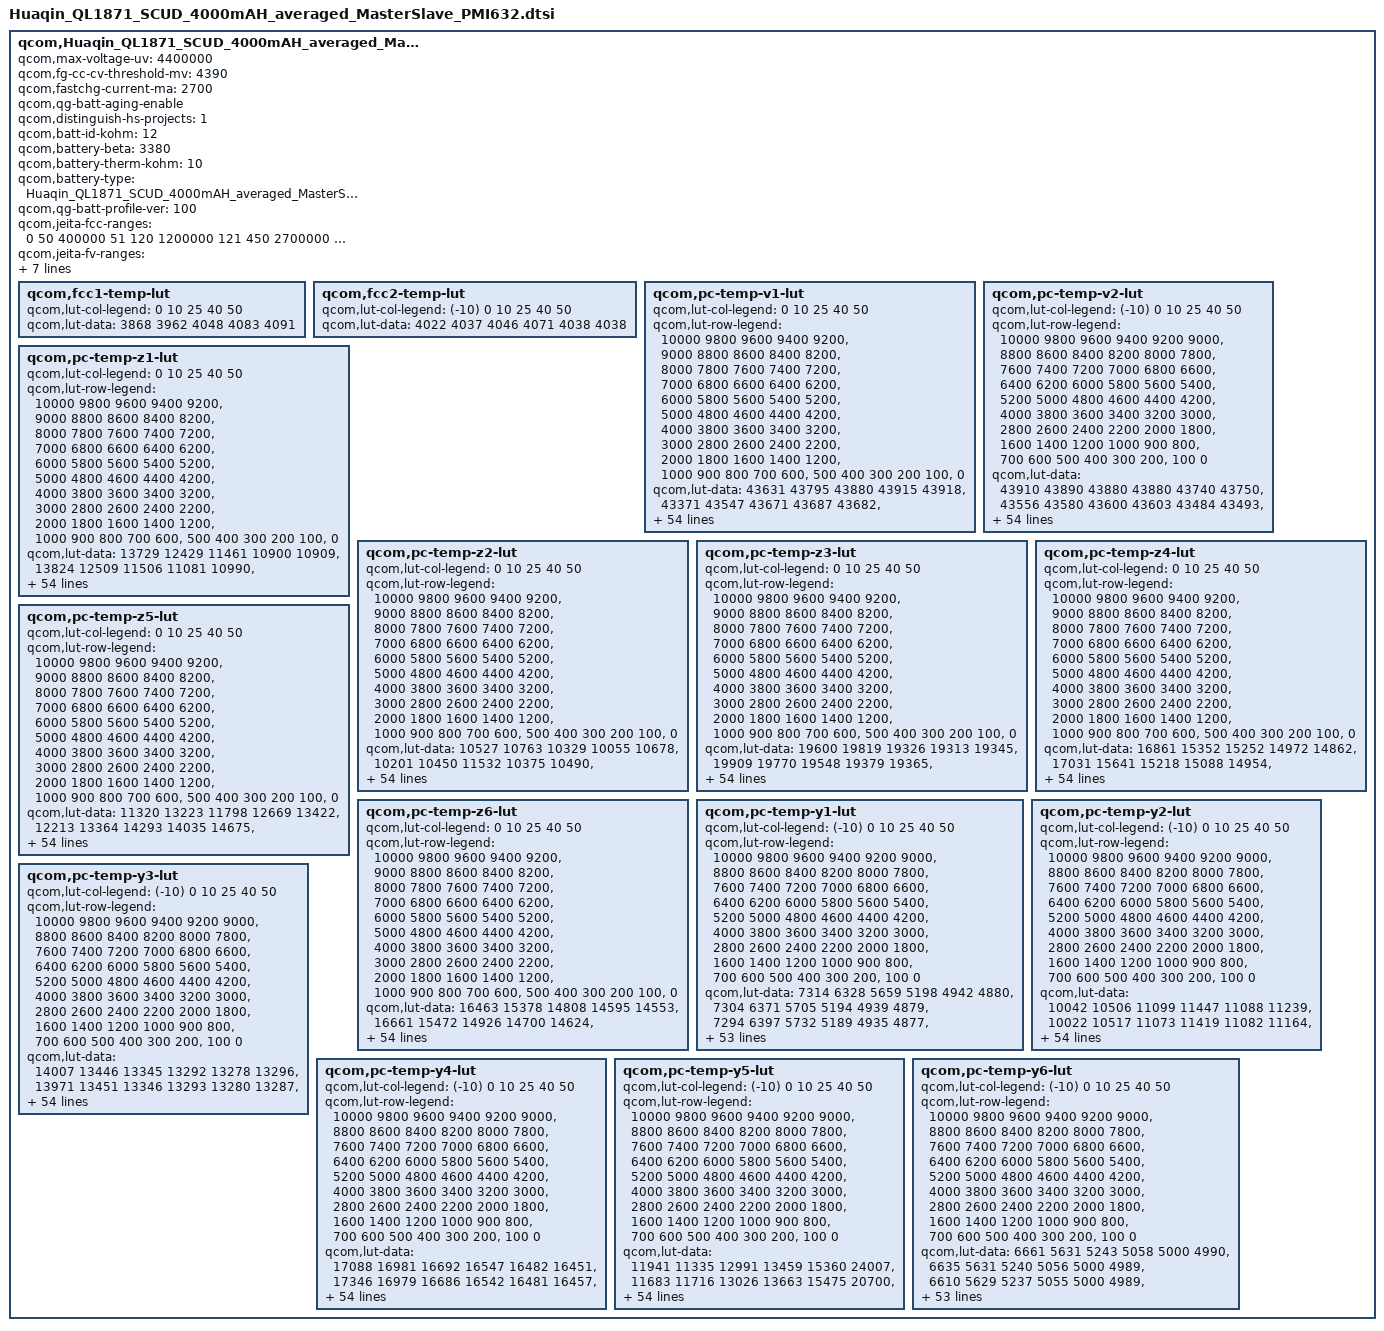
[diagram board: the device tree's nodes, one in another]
qcom,Huaqin_QL1871_SCUD_4000mAH_averaged_MasterSlave_PMI632 {
        /* Huaqin_QL1871_SCUD_4000mAH_averaged_MasterSlave_PMI632 */
	qcom,max-voltage-uv = <4400000>;
	qcom,fg-cc-cv-threshold-mv = <4390>;
	qcom,fastchg-current-ma = <2700>;
	/* HS60 add for SR-ZQL1695-01-357 Import battery aging by gaochao at 2019/08/29 start */
	qcom,qg-batt-aging-enable;
	/* HS60 add for SR-ZQL1695-01-357 Import battery aging by gaochao at 2019/08/29 end */
	/* HS50 add for SR-QL3095-01-67 Distinguish HS60, HS70 and HS50 charging by wenyaqi at 2020/8/3 start */
	qcom,distinguish-hs-projects = <1>;
	/* HS50 add for SR-QL3095-01-67 Distinguish HS60, HS70 and HS50 charging by wenyaqi at 2020/8/3 end */
	qcom,batt-id-kohm = <12>;
	qcom,battery-beta = <3380>;
	qcom,battery-therm-kohm = <10>;
	qcom,battery-type = "Huaqin_QL1871_SCUD_4000mAH_averaged_MasterSlave_PMI632";
	qcom,qg-batt-profile-ver = <100>;

	qcom,jeita-fcc-ranges = <0   50   400000
				 51   120   1200000
				 121 450  2700000
				 451 500  1400000>;
	qcom,jeita-fv-ranges =  <0   50  4400000
				 51   120  4400000
				 121 450  4400000
				 451 500  4200000>;

	/* HS60 add for SR-ZQL1695-01-357 Import battery aging by gaochao at 2019/08/29 start */
	qcom,vfloat-ranges = <0 299 4400000
	                      300 399 4380000
                              400 699 4360000
                              700 999 4340000
                              1000 9999 4290000>;

	qcom,vbat-rechg-ranges = <0 299 4330000
                                  300 399 4310000
                                  400 699 4290000
                                  700 999 4270000
                                  1000 9999 4220000>;
	/* HS60 add for SR-ZQL1695-01-357 Import battery aging by gaochao at 2019/08/29 end */

	/* COOL = 15 DegC, WARM = 45 DegC */
	qcom,jeita-soft-thresholds = <0x2554 0xFDC>;
	/* COLD = 0 DegC, HOT = 50 DegC */
	/* Huaqin add for HS70-733 modify jeita-hard-thresholds to 50 by qianyingdong at 2019/11/26 start */
	qcom,jeita-hard-thresholds = <0x36B9 0xDBF>;
	/* Huaqin add for HS70-733 modify jeita-hard-thresholds to 50 by qianyingdong at 2019/11/26 end */

	qcom,fcc1-temp-lut {
		qcom,lut-col-legend = <0 10 25 40 50>;
		qcom,lut-data = <3868 3962 4048 4083 4091>;
	};

	qcom,fcc2-temp-lut {
		qcom,lut-col-legend = <(-10) 0 10 25 40 50>;
		qcom,lut-data = <4022 4037 4046 4071 4038 4038>;
	};

	qcom,pc-temp-v1-lut {
		qcom,lut-col-legend = <0 10 25 40 50>;
		qcom,lut-row-legend = <10000 9800 9600 9400 9200>,
			<9000 8800 8600 8400 8200>,
			<8000 7800 7600 7400 7200>,
			<7000 6800 6600 6400 6200>,
			<6000 5800 5600 5400 5200>,
			<5000 4800 4600 4400 4200>,
			<4000 3800 3600 3400 3200>,
			<3000 2800 2600 2400 2200>,
			<2000 1800 1600 1400 1200>,
			<1000 900 800 700 600>,
			<500 400 300 200 100>,
			<0>;
		qcom,lut-data = <43631 43795 43880 43915 43918>,
			<43371 43547 43671 43687 43682>,
			<43122 43302 43427 43456 43453>,
			<42881 43059 43176 43223 43221>,
			<42642 42817 42932 42987 42989>,
			<42407 42580 42690 42747 42757>,
			<42177 42347 42453 42509 42525>,
			<41955 42117 42221 42273 42292>,
			<41739 41890 41992 42041 42059>,
			<41530 41667 41763 41809 41829>,
			<41331 41452 41537 41580 41601>,
			<41135 41246 41322 41356 41377>,
			<40932 41043 41118 41139 41156>,
			<40728 40842 40913 40928 40940>,
			<40515 40642 40696 40719 40733>,
			<40276 40437 40480 40516 40533>,
			<40047 40218 40276 40322 40340>,
			<39878 40017 40081 40137 40154>,
			<39747 39860 39905 39960 39975>,
			<39620 39725 39762 39798 39809>,
			<39488 39582 39622 39643 39650>,
			<39357 39430 39437 39462 39470>,
			<39224 39267 39209 39238 39253>,
			<39088 39073 39010 39028 39045>,
			<38956 38854 38851 38867 38879>,
			<38829 38696 38715 38728 38733>,
			<38708 38593 38605 38609 38609>,
			<38603 38513 38513 38506 38504>,
			<38513 38443 38429 38414 38409>,
			<38434 38384 38347 38325 38317>,
			<38370 38329 38274 38244 38233>,
			<38316 38276 38213 38174 38157>,
			<38268 38227 38161 38111 38088>,
			<38227 38182 38114 38056 38025>,
			<38192 38141 38076 38010 37972>,
			<38158 38103 38038 37966 37921>,
			<38128 38071 38001 37914 37857>,
			<38092 38036 37962 37857 37782>,
			<38036 37979 37906 37787 37702>,
			<37960 37891 37814 37701 37619>,
			<37866 37788 37702 37599 37524>,
			<37739 37664 37582 37481 37407>,
			<37599 37524 37446 37344 37267>,
			<37445 37367 37285 37189 37111>,
			<37307 37230 37151 37056 36984>,
			<37221 37149 37071 36977 36911>,
			<37195 37124 37051 36960 36890>,
			<37170 37103 37036 36945 36878>,
			<37145 37082 37019 36922 36857>,
			<37079 37020 36942 36828 36737>,
			<36795 36727 36640 36513 36408>,
			<36325 36268 36184 36054 35952>,
			<35731 35670 35588 35456 35353>,
			<34909 34845 34767 34636 34531>,
			<33598 33534 33467 33344 33235>,
			<30000 30000 30000 30000 30000>;
	};

	qcom,pc-temp-v2-lut {
		qcom,lut-col-legend = <(-10) 0 10 25 40 50>;
		qcom,lut-row-legend = <10000 9800 9600 9400 9200 9000>,
			<8800 8600 8400 8200 8000 7800>,
			<7600 7400 7200 7000 6800 6600>,
			<6400 6200 6000 5800 5600 5400>,
			<5200 5000 4800 4600 4400 4200>,
			<4000 3800 3600 3400 3200 3000>,
			<2800 2600 2400 2200 2000 1800>,
			<1600 1400 1200 1000 900 800>,
			<700 600 500 400 300 200>,
			<100 0>;
		qcom,lut-data = <43910 43890 43880 43880 43740 43750>,
			<43556 43580 43600 43603 43484 43493>,
			<43226 43289 43333 43339 43235 43243>,
			<42921 43018 43078 43087 42993 43001>,
			<42638 42768 42836 42849 42759 42766>,
			<42376 42524 42598 42613 42526 42534>,
			<42139 42280 42360 42375 42293 42303>,
			<41916 42041 42125 42140 42061 42073>,
			<41675 41814 41897 41909 41832 41845>,
			<41414 41595 41673 41681 41605 41618>,
			<41198 41380 41453 41455 41382 41395>,
			<41062 41170 41235 41229 41164 41176>,
			<40935 40962 41020 41008 40949 40960>,
			<40699 40753 40816 40803 40744 40753>,
			<40302 40542 40621 40607 40545 40549>,
			<39947 40309 40409 40405 40348 40353>,
			<39691 40016 40158 40191 40148 40163>,
			<39475 39725 39904 39984 39956 39981>,
			<39302 39516 39685 39806 39785 39808>,
			<39164 39351 39484 39641 39631 39643>,
			<39020 39190 39297 39452 39457 39463>,
			<38857 39025 39118 39225 39238 39247>,
			<38695 38868 38953 39009 39018 39033>,
			<38549 38721 38801 38836 38838 38853>,
			<38412 38581 38661 38684 38680 38694>,
			<38299 38455 38534 38552 38547 38558>,
			<38210 38344 38418 38437 38436 38444>,
			<38133 38240 38313 38334 38337 38343>,
			<38062 38134 38220 38242 38246 38250>,
			<37998 38031 38133 38157 38162 38164>,
			<37937 37954 38051 38079 38087 38086>,
			<37877 37898 37970 38005 38019 38013>,
			<37818 37850 37896 37938 37954 37943>,
			<37759 37799 37833 37880 37887 37874>,
			<37700 37750 37777 37825 37819 37805>,
			<37641 37702 37730 37764 37741 37720>,
			<37584 37658 37692 37700 37647 37603>,
			<37526 37611 37651 37632 37551 37488>,
			<37462 37548 37595 37564 37468 37397>,
			<37397 37473 37527 37491 37388 37314>,
			<37331 37390 37447 37405 37299 37223>,
			<37267 37291 37346 37304 37199 37122>,
			<37196 37192 37224 37178 37075 37000>,
			<37114 37096 37085 37036 36931 36859>,
			<37024 37006 36971 36922 36840 36771>,
			<36915 36903 36912 36887 36814 36750>,
			<36847 36855 36892 36871 36796 36731>,
			<36766 36795 36864 36849 36775 36708>,
			<36663 36719 36818 36801 36727 36652>,
			<36501 36587 36687 36629 36533 36412>,
			<36226 36314 36325 36241 36120 35984>,
			<35813 35836 35779 35685 35572 35423>,
			<35206 35174 35054 34950 34851 34690>,
			<34271 34222 34035 33866 33828 33639>,
			<32424 32566 32408 32669 32501 32439>,
			<28145 27586 27058 27230 27853 27986>;
	};

	qcom,pc-temp-z1-lut {
		qcom,lut-col-legend = <0 10 25 40 50>;
		qcom,lut-row-legend = <10000 9800 9600 9400 9200>,
			<9000 8800 8600 8400 8200>,
			<8000 7800 7600 7400 7200>,
			<7000 6800 6600 6400 6200>,
			<6000 5800 5600 5400 5200>,
			<5000 4800 4600 4400 4200>,
			<4000 3800 3600 3400 3200>,
			<3000 2800 2600 2400 2200>,
			<2000 1800 1600 1400 1200>,
			<1000 900 800 700 600>,
			<500 400 300 200 100>,
			<0>;
		qcom,lut-data = <13729 12429 11461 10900 10909>,
			<13824 12509 11506 11081 10990>,
			<13858 12550 11519 11095 11001>,
			<13876 12548 11523 11104 11006>,
			<13871 12544 11522 11106 11010>,
			<13833 12538 11519 11106 11014>,
			<13800 12522 11515 11106 11015>,
			<13789 12508 11508 11105 11013>,
			<13781 12502 11502 11104 11009>,
			<13783 12498 11500 11101 11009>,
			<13814 12499 11498 11096 11011>,
			<13842 12508 11498 11094 11013>,
			<13820 12516 11498 11096 11010>,
			<13758 12501 11498 11099 11007>,
			<13731 12465 11497 11098 11005>,
			<13736 12452 11495 11094 11004>,
			<13744 12450 11493 11093 11004>,
			<13749 12449 11491 11097 11006>,
			<13752 12452 11490 11100 11009>,
			<13756 12458 11493 11100 11011>,
			<13764 12461 11498 11101 11014>,
			<13776 12462 11502 11102 11016>,
			<13791 12462 11505 11106 11018>,
			<13812 12474 11509 11110 11020>,
			<13827 12502 11516 11112 11023>,
			<13822 12513 11524 11114 11027>,
			<13811 12509 11529 11117 11030>,
			<13808 12504 11532 11123 11032>,
			<13828 12505 11537 11128 11034>,
			<13849 12510 11546 11129 11036>,
			<13839 12515 11556 11130 11039>,
			<13799 12518 11560 11133 11041>,
			<13778 12522 11562 11138 11042>,
			<13803 12527 11565 11143 11044>,
			<13842 12534 11570 11147 11046>,
			<13860 12541 11574 11149 11048>,
			<13872 12555 11580 11149 11052>,
			<13877 12566 11587 11149 11056>,
			<13874 12568 11593 11149 11057>,
			<13866 12568 11597 11155 11057>,
			<13864 12568 11601 11162 11057>,
			<13864 12578 11605 11161 11058>,
			<13865 12588 11609 11161 11060>,
			<13868 12590 11613 11160 11062>,
			<13798 12589 11614 11162 11064>,
			<13818 12557 11618 11164 11064>,
			<13817 12583 11620 11165 11066>,
			<13809 12563 11622 11167 11062>,
			<13811 12577 11622 11165 11064>,
			<13846 12581 11626 11167 11066>,
			<13836 12601 11629 11174 11066>,
			<13857 12610 11646 11179 11073>,
			<13872 12643 11665 11184 11087>,
			<13910 12685 11692 11207 11097>,
			<13910 12685 11692 11207 11097>,
			<13910 12685 11692 11207 11097>;
	};

	qcom,pc-temp-z2-lut {
		qcom,lut-col-legend = <0 10 25 40 50>;
		qcom,lut-row-legend = <10000 9800 9600 9400 9200>,
			<9000 8800 8600 8400 8200>,
			<8000 7800 7600 7400 7200>,
			<7000 6800 6600 6400 6200>,
			<6000 5800 5600 5400 5200>,
			<5000 4800 4600 4400 4200>,
			<4000 3800 3600 3400 3200>,
			<3000 2800 2600 2400 2200>,
			<2000 1800 1600 1400 1200>,
			<1000 900 800 700 600>,
			<500 400 300 200 100>,
			<0>;
		qcom,lut-data = <10527 10763 10329 10055 10678>,
			<10201 10450 11532 10375 10490>,
			<10171 10275 10970 10466 10603>,
			<10158 10239 10531 10626 10661>,
			<10157 10220 10536 10673 10664>,
			<10160 10220 10565 10686 10607>,
			<10165 10245 10651 10691 10533>,
			<10173 10275 10967 10674 10440>,
			<10184 10297 11184 10652 10354>,
			<10198 10317 11194 10666 10364>,
			<10220 10330 11198 10724 10472>,
			<10236 10339 11169 10751 10530>,
			<10229 10349 11015 10740 10442>,
			<10205 10365 10909 10717 10332>,
			<10188 10387 10898 10638 10327>,
			<10179 10413 10891 10475 10351>,
			<10173 10447 10844 10411 10361>,
			<10187 10476 10699 10405 10343>,
			<10245 10491 10623 10402 10324>,
			<10281 10502 10625 10416 10345>,
			<10272 10501 10629 10460 10405>,
			<10253 10436 10630 10538 10435>,
			<10228 10358 10630 10742 10443>,
			<10187 10319 10631 10883 10453>,
			<10154 10290 10642 10844 10500>,
			<10144 10282 10657 10757 10573>,
			<10139 10289 10667 10684 10585>,
			<10138 10302 10676 10614 10546>,
			<10147 10320 10676 10567 10494>,
			<10162 10348 10620 10544 10422>,
			<10176 10362 10562 10529 10351>,
			<10191 10366 10560 10522 10346>,
			<10208 10369 10566 10518 10371>,
			<10233 10378 10574 10517 10397>,
			<10261 10395 10584 10527 10414>,
			<10292 10406 10599 10550 10434>,
			<10327 10408 10621 10633 10491>,
			<10350 10410 10652 10816 10601>,
			<10354 10419 10689 10885 10642>,
			<10356 10441 10742 10871 10591>,
			<10359 10455 10780 10856 10539>,
			<10362 10458 10787 10867 10576>,
			<10374 10461 10790 10887 10649>,
			<10471 10503 10783 10870 10590>,
			<10775 10572 10805 10788 10524>,
			<10899 10767 10805 10713 10515>,
			<10383 10849 10841 10648 10463>,
			<10298 10976 10809 10598 10629>,
			<10224 11087 10885 10702 10568>,
			<10246 10856 10887 10774 10576>,
			<10422 10984 11054 10633 10266>,
			<10992 10963 11025 10407 10306>,
			<10035 11054 10946 10340 10210>,
			<9837 10906 10788 10263 10124>,
			<9837 10906 10788 10263 10124>,
			<9837 10906 10788 10263 10124>;
	};

	qcom,pc-temp-z3-lut {
		qcom,lut-col-legend = <0 10 25 40 50>;
		qcom,lut-row-legend = <10000 9800 9600 9400 9200>,
			<9000 8800 8600 8400 8200>,
			<8000 7800 7600 7400 7200>,
			<7000 6800 6600 6400 6200>,
			<6000 5800 5600 5400 5200>,
			<5000 4800 4600 4400 4200>,
			<4000 3800 3600 3400 3200>,
			<3000 2800 2600 2400 2200>,
			<2000 1800 1600 1400 1200>,
			<1000 900 800 700 600>,
			<500 400 300 200 100>,
			<0>;
		qcom,lut-data = <19600 19819 19326 19313 19345>,
			<19909 19770 19548 19379 19365>,
			<19997 19750 19552 19411 19392>,
			<20042 19773 19554 19432 19411>,
			<20048 19814 19550 19434 19413>,
			<20046 19819 19542 19430 19401>,
			<20043 19778 19534 19425 19389>,
			<20031 19736 19528 19416 19383>,
			<20009 19719 19521 19407 19378>,
			<19990 19706 19506 19405 19374>,
			<19971 19695 19489 19405 19370>,
			<19959 19685 19490 19403 19367>,
			<19955 19677 19509 19391 19363>,
			<19954 19670 19520 19375 19358>,
			<19953 19665 19511 19369 19352>,
			<19958 19660 19493 19365 19343>,
			<19964 19656 19473 19359 19336>,
			<19948 19650 19445 19347 19331>,
			<19880 19629 19433 19338 19329>,
			<19838 19592 19435 19341 19329>,
			<19849 19581 19440 19351 19332>,
			<19873 19607 19455 19358 19336>,
			<19906 19646 19489 19362 19341>,
			<19965 19690 19503 19368 19349>,
			<20016 19741 19475 19388 19366>,
			<20038 19758 19442 19413 19389>,
			<20054 19748 19445 19416 19392>,
			<20058 19731 19464 19407 19379>,
			<20049 19713 19484 19401 19369>,
			<20034 19691 19504 19401 19367>,
			<20016 19674 19517 19400 19365>,
			<19990 19660 19514 19398 19364>,
			<19963 19650 19502 19391 19364>,
			<19938 19647 19490 19383 19362>,
			<19913 19647 19479 19376 19356>,
			<19888 19645 19470 19370 19350>,
			<19859 19643 19465 19370 19349>,
			<19843 19640 19463 19371 19351>,
			<19845 19636 19459 19371 19351>,
			<19849 19633 19454 19369 19348>,
			<19849 19629 19450 19367 19345>,
			<19839 19626 19447 19367 19345>,
			<19816 19620 19445 19369 19348>,
			<19736 19593 19441 19364 19349>,
			<19601 19567 19431 19359 19345>,
			<19431 19507 19421 19356 19335>,
			<19350 19478 19405 19338 19333>,
			<19343 19442 19399 19337 19320>,
			<19336 19424 19376 19342 19312>,
			<19331 19474 19382 19330 19333>,
			<19356 19450 19369 19322 19353>,
			<19444 19452 19363 19337 19330>,
			<19369 19405 19378 19344 19345>,
			<19378 19399 19368 19361 19342>,
			<19378 19399 19368 19361 19342>,
			<19378 19399 19368 19361 19342>;
	};

	qcom,pc-temp-z4-lut {
		qcom,lut-col-legend = <0 10 25 40 50>;
		qcom,lut-row-legend = <10000 9800 9600 9400 9200>,
			<9000 8800 8600 8400 8200>,
			<8000 7800 7600 7400 7200>,
			<7000 6800 6600 6400 6200>,
			<6000 5800 5600 5400 5200>,
			<5000 4800 4600 4400 4200>,
			<4000 3800 3600 3400 3200>,
			<3000 2800 2600 2400 2200>,
			<2000 1800 1600 1400 1200>,
			<1000 900 800 700 600>,
			<500 400 300 200 100>,
			<0>;
		qcom,lut-data = <16861 15352 15252 14972 14862>,
			<17031 15641 15218 15088 14954>,
			<16860 15761 15236 15042 14932>,
			<16569 15664 15250 14958 14874>,
			<16354 15463 15204 14925 14854>,
			<16173 15337 15106 14913 14850>,
			<16019 15258 15043 14902 14847>,
			<15897 15201 15000 14891 14841>,
			<15794 15165 14972 14881 14834>,
			<15702 15139 14958 14866 14824>,
			<15612 15119 14948 14846 14813>,
			<15544 15103 14923 14836 14802>,
			<15511 15090 14868 14834 14795>,
			<15490 15078 14838 14832 14788>,
			<15471 15066 14841 14825 14782>,
			<15453 15052 14848 14811 14776>,
			<15435 15031 14854 14800 14769>,
			<15419 15013 14860 14792 14760>,
			<15405 15005 14862 14784 14752>,
			<15386 15000 14844 14772 14744>,
			<15348 14993 14820 14759 14737>,
			<15298 14981 14842 14771 14743>,
			<15251 14972 14940 14891 14828>,
			<15199 15008 15030 14982 14900>,
			<15168 15105 15103 14967 14888>,
			<15169 15143 15153 14933 14859>,
			<15175 15131 15137 14907 14840>,
			<15179 15110 15067 14886 14830>,
			<15183 15086 15004 14865 14819>,
			<15186 15056 14952 14842 14805>,
			<15186 15031 14910 14820 14790>,
			<15184 15012 14885 14804 14774>,
			<15182 14994 14868 14789 14758>,
			<15178 14976 14855 14780 14748>,
			<15173 14956 14844 14774 14745>,
			<15171 14941 14837 14770 14743>,
			<15170 14930 14836 14777 14753>,
			<15169 14922 14835 14799 14788>,
			<15150 14923 14838 14814 14802>,
			<15118 14929 14869 14822 14798>,
			<15108 14932 14894 14826 14792>,
			<15110 14926 14884 14818 14782>,
			<15118 14922 14870 14805 14771>,
			<15173 14939 14876 14813 14779>,
			<15173 14911 14862 14812 14781>,
			<15285 14910 14814 14780 14756>,
			<15363 14922 14795 14767 14738>,
			<15360 14943 14765 14733 14714>,
			<15354 14953 14757 14695 14693>,
			<15347 14899 14776 14737 14706>,
			<15347 14962 14840 14773 14707>,
			<15270 14972 14854 14760 14727>,
			<15383 15035 14840 14753 14712>,
			<15404 15057 14859 14736 14717>,
			<15404 15057 14859 14736 14717>,
			<15404 15057 14859 14736 14717>;
	};

	qcom,pc-temp-z5-lut {
		qcom,lut-col-legend = <0 10 25 40 50>;
		qcom,lut-row-legend = <10000 9800 9600 9400 9200>,
			<9000 8800 8600 8400 8200>,
			<8000 7800 7600 7400 7200>,
			<7000 6800 6600 6400 6200>,
			<6000 5800 5600 5400 5200>,
			<5000 4800 4600 4400 4200>,
			<4000 3800 3600 3400 3200>,
			<3000 2800 2600 2400 2200>,
			<2000 1800 1600 1400 1200>,
			<1000 900 800 700 600>,
			<500 400 300 200 100>,
			<0>;
		qcom,lut-data = <11320 13223 11798 12669 13422>,
			<12213 13364 14293 14035 14675>,
			<12538 13603 14487 15227 16188>,
			<12741 14081 14641 16274 18120>,
			<12914 14657 15070 16609 18453>,
			<13075 14787 15553 16749 17710>,
			<13158 14752 15646 16795 17033>,
			<13165 14725 15571 16573 16751>,
			<13168 14752 15472 16278 16560>,
			<13186 14813 15339 16354 16479>,
			<13295 14848 15206 16762 16438>,
			<13392 14868 15356 16934 16399>,
			<13397 14878 16240 16352 16362>,
			<13396 14754 16784 15637 16315>,
			<13398 14484 16527 15440 16069>,
			<13485 14420 16096 15350 15465>,
			<13588 14681 15846 15208 15215>,
			<13538 14920 15661 14886 15236>,
			<13279 14814 15597 14647 15283>,
			<13120 14537 16237 15383 15663>,
			<13324 14488 17566 16998 16494>,
			<13814 15394 19813 17344 16657>,
			<14506 16962 23654 16412 15531>,
			<15815 19599 25186 15651 14586>,
			<17114 23481 20908 15559 14926>,
			<18022 24817 15997 15512 15621>,
			<18776 22907 15525 15513 15751>,
			<18984 20339 15498 15569 15513>,
			<18807 18791 15555 15674 15352>,
			<18498 17545 16934 16244 15659>,
			<18079 16955 18677 17140 16331>,
			<17444 16733 19499 17723 17095>,
			<16862 16617 20071 18153 18106>,
			<16411 16748 20462 18598 18944>,
			<16010 17252 20712 19155 19608>,
			<15633 17634 20942 19661 20051>,
			<15238 17796 21305 19979 19936>,
			<15030 17926 21701 20223 19333>,
			<15300 18108 21710 20236 18668>,
			<15813 18335 20720 19159 17817>,
			<15959 18434 19689 18057 17202>,
			<15823 18379 19344 17928 17224>,
			<15494 18221 19059 17871 17320>,
			<14309 16702 18224 16848 17093>,
			<13495 16648 17954 16289 16087>,
			<12075 14947 18042 16435 15311>,
			<11510 14081 17033 15429 15738>,
			<11451 13309 17072 16235 15267>,
			<11411 12957 15631 19601 15968>,
			<11420 14139 16012 15518 16363>,
			<11640 13460 13856 13274 16674>,
			<12143 13265 13348 13733 13941>,
			<11504 12415 13518 13897 14829>,
			<11419 12195 13036 14647 14160>,
			<11419 12195 13036 14647 14160>,
			<11419 12195 13036 14647 14160>;
	};

	qcom,pc-temp-z6-lut {
		qcom,lut-col-legend = <0 10 25 40 50>;
		qcom,lut-row-legend = <10000 9800 9600 9400 9200>,
			<9000 8800 8600 8400 8200>,
			<8000 7800 7600 7400 7200>,
			<7000 6800 6600 6400 6200>,
			<6000 5800 5600 5400 5200>,
			<5000 4800 4600 4400 4200>,
			<4000 3800 3600 3400 3200>,
			<3000 2800 2600 2400 2200>,
			<2000 1800 1600 1400 1200>,
			<1000 900 800 700 600>,
			<500 400 300 200 100>,
			<0>;
		qcom,lut-data = <16463 15378 14808 14595 14553>,
			<16661 15472 14926 14700 14624>,
			<16597 15508 14936 14693 14625>,
			<16485 15476 14939 14676 14616>,
			<16389 15402 14917 14665 14608>,
			<16297 15338 14869 14658 14600>,
			<16213 15278 14838 14650 14593>,
			<16141 15231 14818 14641 14587>,
			<16078 15204 14800 14631 14581>,
			<16023 15184 14786 14623 14574>,
			<15974 15169 14773 14615 14567>,
			<15935 15158 14760 14607 14560>,
			<15909 15147 14746 14600 14554>,
			<15890 15132 14736 14592 14549>,
			<15876 15116 14731 14584 14542>,
			<15867 15103 14727 14577 14535>,
			<15858 15094 14720 14568 14529>,
			<15839 15084 14709 14557 14522>,
			<15805 15068 14700 14549 14517>,
			<15781 15049 14693 14548 14515>,
			<15772 15043 14688 14547 14513>,
			<15767 15053 14705 14554 14517>,
			<15767 15072 14768 14611 14559>,
			<15780 15113 14810 14655 14596>,
			<15797 15183 14827 14655 14597>,
			<15812 15208 14836 14654 14598>,
			<15827 15199 14831 14652 14596>,
			<15831 15184 14813 14638 14586>,
			<15832 15167 14797 14624 14574>,
			<15832 15146 14786 14614 14566>,
			<15828 15128 14776 14604 14559>,
			<15816 15114 14764 14595 14551>,
			<15803 15103 14751 14586 14544>,
			<15792 15095 14740 14578 14538>,
			<15781 15090 14729 14571 14532>,
			<15774 15086 14722 14566 14528>,
			<15767 15083 14720 14569 14533>,
			<15762 15080 14719 14580 14548>,
			<15760 15081 14720 14586 14555>,
			<15757 15086 14731 14589 14552>,
			<15757 15088 14740 14590 14547>,
			<15758 15088 14736 14587 14543>,
			<15757 15087 14729 14581 14540>,
			<15740 15083 14730 14583 14544>,
			<15677 15063 14721 14580 14543>,
			<15646 15034 14695 14565 14528>,
			<15639 15024 14680 14550 14520>,
			<15632 15016 14664 14534 14502>,
			<15630 15012 14648 14521 14487>,
			<15637 15020 14661 14532 14505>,
			<15663 15041 14683 14546 14518>,
			<15691 15055 14690 14550 14517>,
			<15717 15069 14696 14553 14521>,
			<15766 15093 14705 14559 14526>,
			<15766 15093 14705 14559 14526>,
			<15766 15093 14705 14559 14526>;
	};

	qcom,pc-temp-y1-lut {
		qcom,lut-col-legend = <(-10) 0 10 25 40 50>;
		qcom,lut-row-legend = <10000 9800 9600 9400 9200 9000>,
			<8800 8600 8400 8200 8000 7800>,
			<7600 7400 7200 7000 6800 6600>,
			<6400 6200 6000 5800 5600 5400>,
			<5200 5000 4800 4600 4400 4200>,
			<4000 3800 3600 3400 3200 3000>,
			<2800 2600 2400 2200 2000 1800>,
			<1600 1400 1200 1000 900 800>,
			<700 600 500 400 300 200>,
			<100 0>;
		qcom,lut-data = <7314 6328 5659 5198 4942 4880>,
			<7304 6371 5705 5194 4939 4879>,
			<7294 6397 5732 5189 4935 4877>,
			<7284 6410 5746 5184 4932 4876>,
			<7275 6415 5751 5178 4929 4875>,
			<7269 6415 5751 5172 4927 4874>,
			<7265 6395 5740 5164 4926 4873>,
			<7263 6366 5722 5157 4925 4873>,
			<7265 6363 5713 5153 4924 4872>,
			<7274 6367 5707 5150 4923 4871>,
			<7279 6369 5702 5148 4921 4871>,
			<7268 6360 5696 5145 4920 4871>,
			<7253 6349 5691 5143 4919 4871>,
			<7252 6347 5686 5141 4919 4872>,
			<7256 6347 5682 5139 4919 4874>,
			<7261 6347 5681 5139 4919 4874>,
			<7272 6359 5684 5139 4921 4872>,
			<7283 6373 5688 5140 4922 4870>,
			<7284 6373 5690 5142 4922 4869>,
			<7278 6369 5691 5144 4920 4869>,
			<7271 6363 5692 5146 4919 4869>,
			<7258 6347 5691 5147 4921 4871>,
			<7246 6332 5690 5148 4923 4873>,
			<7249 6338 5691 5150 4924 4873>,
			<7262 6358 5695 5154 4925 4873>,
			<7268 6366 5697 5157 4927 4874>,
			<7256 6362 5698 5159 4929 4875>,
			<7240 6357 5699 5161 4931 4877>,
			<7234 6355 5702 5164 4934 4878>,
			<7231 6353 5708 5168 4939 4880>,
			<7226 6350 5709 5172 4941 4882>,
			<7212 6339 5709 5176 4941 4885>,
			<7195 6329 5708 5180 4942 4888>,
			<7185 6332 5711 5184 4944 4891>,
			<7178 6340 5716 5189 4948 4894>,
			<7176 6342 5717 5193 4950 4894>,
			<7177 6340 5716 5197 4951 4891>,
			<7178 6337 5715 5199 4952 4889>,
			<7176 6334 5712 5201 4953 4891>,
			<7168 6330 5708 5202 4954 4896>,
			<7157 6330 5709 5205 4955 4898>,
			<7132 6337 5721 5211 4957 4899>,
			<7122 6335 5735 5218 4959 4901>,
			<7141 6316 5746 5223 4962 4905>,
			<7214 6328 5743 5226 4963 4906>,
			<7205 6376 5757 5225 4963 4904>,
			<7214 6362 5737 5232 4963 4907>,
			<7250 6362 5746 5236 4965 4904>,
			<7227 6374 5773 5240 4967 4906>,
			<7198 6373 5787 5242 4972 4907>,
			<7198 6336 5778 5245 4974 4915>,
			<7199 6378 5805 5255 4975 4913>,
			<7207 6384 5797 5276 4985 4922>,
			<7278 6390 5827 5293 4999 4931>,
			<7278 6390 5827 5293 4999 4931>,
			<7278 6390 5827 5293 4999 4931>;
	};

	qcom,pc-temp-y2-lut {
		qcom,lut-col-legend = <(-10) 0 10 25 40 50>;
		qcom,lut-row-legend = <10000 9800 9600 9400 9200 9000>,
			<8800 8600 8400 8200 8000 7800>,
			<7600 7400 7200 7000 6800 6600>,
			<6400 6200 6000 5800 5600 5400>,
			<5200 5000 4800 4600 4400 4200>,
			<4000 3800 3600 3400 3200 3000>,
			<2800 2600 2400 2200 2000 1800>,
			<1600 1400 1200 1000 900 800>,
			<700 600 500 400 300 200>,
			<100 0>;
		qcom,lut-data = <10042 10506 11099 11447 11088 11239>,
			<10022 10517 11073 11419 11082 11164>,
			<10018 10527 11042 11364 11079 11094>,
			<10028 10537 11010 11302 11079 11037>,
			<10047 10548 10984 11251 11081 10999>,
			<10073 10558 10969 11231 11086 10986>,
			<10104 10570 10964 11229 11106 11004>,
			<10148 10580 10960 11228 11140 11030>,
			<10236 10580 10951 11229 11174 11030>,
			<10416 10577 10936 11236 11215 11013>,
			<10511 10576 10925 11248 11240 10996>,
			<10510 10587 10918 11284 11250 10985>,
			<10508 10613 10914 11317 11255 10972>,
			<10521 10670 10914 11308 11242 10938>,
			<10587 10786 10915 11275 11191 10873>,
			<10669 10839 10919 11269 11169 10848>,
			<10778 10828 10949 11370 11267 11010>,
			<10883 10816 10989 11466 11412 11220>,
			<10924 10829 11009 11465 11505 11292>,
			<10947 10881 11023 11451 11583 11333>,
			<10946 10928 11044 11429 11607 11343>,
			<10426 10959 11089 11378 11557 11301>,
			<9774 10990 11138 11343 11477 11240>,
			<9685 11031 11171 11372 11397 11195>,
			<9676 11079 11198 11437 11309 11154>,
			<9673 11095 11223 11484 11282 11143>,
			<9671 11083 11251 11523 11322 11166>,
			<9669 11071 11268 11542 11370 11211>,
			<9668 11116 11258 11531 11389 11327>,
			<9666 11235 11235 11512 11401 11526>,
			<9665 11274 11224 11513 11431 11588>,
			<9664 11218 11219 11530 11561 11539>,
			<9662 11150 11218 11540 11699 11495>,
			<9662 11115 11218 11534 11769 11592>,
			<9661 11088 11220 11522 11820 11812>,
			<9660 11053 11217 11511 11804 11843>,
			<9659 11004 11193 11499 11538 11493>,
			<9658 10953 11164 11486 11314 11200>,
			<9658 10918 11139 11469 11340 11216>,
			<9657 10884 11115 11454 11402 11259>,
			<9657 10721 11090 11449 11412 11268>,
			<9657 9969 11064 11445 11364 11238>,
			<9656 9698 11036 11402 11348 11188>,
			<9656 9680 11010 11337 11347 11100>,
			<9656 9672 10999 11300 11168 10999>,
			<9656 9673 11017 11335 11185 10990>,
			<9655 9669 10959 11331 11168 10944>,
			<9655 9666 10895 11294 11104 10962>,
			<9655 9663 10866 11251 11142 11027>,
			<9655 9661 10818 11258 11142 10931>,
			<9654 9659 10723 11218 11094 10837>,
			<9654 9656 10606 11112 11013 10729>,
			<9653 9654 10457 10977 10915 10752>,
			<9651 9653 10285 10866 10856 10646>,
			<9651 9653 10285 10866 10856 10646>,
			<9651 9653 10285 10866 10856 10646>;
	};

	qcom,pc-temp-y3-lut {
		qcom,lut-col-legend = <(-10) 0 10 25 40 50>;
		qcom,lut-row-legend = <10000 9800 9600 9400 9200 9000>,
			<8800 8600 8400 8200 8000 7800>,
			<7600 7400 7200 7000 6800 6600>,
			<6400 6200 6000 5800 5600 5400>,
			<5200 5000 4800 4600 4400 4200>,
			<4000 3800 3600 3400 3200 3000>,
			<2800 2600 2400 2200 2000 1800>,
			<1600 1400 1200 1000 900 800>,
			<700 600 500 400 300 200>,
			<100 0>;
		qcom,lut-data = <14007 13446 13345 13292 13278 13296>,
			<13971 13451 13346 13293 13280 13287>,
			<13926 13461 13347 13295 13282 13282>,
			<13882 13473 13348 13298 13283 13279>,
			<13849 13484 13348 13300 13285 13278>,
			<13836 13488 13348 13301 13286 13278>,
			<13843 13488 13348 13301 13287 13281>,
			<13852 13488 13348 13301 13288 13285>,
			<13849 13489 13350 13303 13289 13287>,
			<13821 13495 13359 13308 13289 13289>,
			<13782 13502 13366 13311 13290 13289>,
			<13701 13512 13370 13308 13294 13289>,
			<13617 13521 13373 13304 13298 13289>,
			<13611 13517 13380 13306 13298 13288>,
			<13634 13495 13390 13313 13297 13287>,
			<13646 13480 13394 13315 13295 13287>,
			<13581 13476 13391 13316 13295 13289>,
			<13494 13472 13386 13316 13295 13291>,
			<13482 13462 13380 13317 13295 13291>,
			<13482 13443 13372 13320 13296 13291>,
			<13481 13430 13365 13321 13297 13291>,
			<13480 13424 13358 13315 13293 13288>,
			<13478 13418 13351 13308 13288 13283>,
			<13474 13408 13344 13304 13285 13280>,
			<13466 13395 13338 13301 13282 13278>,
			<13459 13391 13334 13298 13280 13278>,
			<13454 13395 13333 13297 13280 13278>,
			<13451 13399 13332 13296 13280 13278>,
			<13454 13387 13335 13298 13280 13278>,
			<13469 13356 13344 13301 13280 13279>,
			<13487 13345 13346 13302 13281 13279>,
			<13509 13356 13346 13302 13284 13279>,
			<13534 13368 13346 13302 13286 13279>,
			<13561 13371 13345 13304 13287 13279>,
			<13590 13373 13343 13306 13287 13281>,
			<13626 13376 13343 13307 13287 13281>,
			<13673 13390 13348 13306 13284 13279>,
			<13728 13402 13352 13306 13281 13276>,
			<13784 13404 13355 13304 13281 13276>,
			<13845 13405 13357 13303 13281 13277>,
			<13912 13408 13357 13302 13281 13277>,
			<13993 13414 13355 13302 13281 13278>,
			<14071 13427 13354 13302 13281 13278>,
			<14142 13456 13351 13302 13278 13278>,
			<14199 13496 13336 13298 13283 13278>,
			<14068 13472 13334 13299 13286 13286>,
			<14155 13513 13348 13301 13287 13287>,
			<14248 13555 13357 13308 13295 13291>,
			<14354 13614 13372 13319 13302 13296>,
			<14459 13697 13378 13311 13297 13288>,
			<14580 13801 13367 13312 13290 13287>,
			<14765 13947 13378 13318 13294 13289>,
			<15008 14241 13401 13330 13302 13297>,
			<15671 14579 13467 13346 13309 13301>,
			<15671 14579 13467 13346 13309 13301>,
			<15671 14579 13467 13346 13309 13301>;
	};

	qcom,pc-temp-y4-lut {
		qcom,lut-col-legend = <(-10) 0 10 25 40 50>;
		qcom,lut-row-legend = <10000 9800 9600 9400 9200 9000>,
			<8800 8600 8400 8200 8000 7800>,
			<7600 7400 7200 7000 6800 6600>,
			<6400 6200 6000 5800 5600 5400>,
			<5200 5000 4800 4600 4400 4200>,
			<4000 3800 3600 3400 3200 3000>,
			<2800 2600 2400 2200 2000 1800>,
			<1600 1400 1200 1000 900 800>,
			<700 600 500 400 300 200>,
			<100 0>;
		qcom,lut-data = <17088 16981 16692 16547 16482 16451>,
			<17346 16979 16686 16542 16481 16457>,
			<17510 16977 16684 16539 16481 16463>,
			<17602 16975 16685 16539 16481 16468>,
			<17642 16973 16688 16541 16481 16471>,
			<17650 16972 16693 16544 16482 16473>,
			<17587 16971 16701 16553 16485 16471>,
			<17485 16971 16710 16564 16490 16469>,
			<17437 16969 16713 16570 16496 16470>,
			<17407 16966 16713 16575 16504 16473>,
			<17397 16963 16714 16582 16510 16478>,
			<17599 16963 16718 16603 16514 16485>,
			<17878 16962 16727 16629 16517 16495>,
			<17815 16987 16742 16645 16526 16506>,
			<17380 17075 16771 16657 16544 16518>,
			<17141 17116 16782 16671 16561 16528>,
			<17177 16987 16769 16693 16575 16533>,
			<17225 16834 16744 16709 16588 16539>,
			<17218 16819 16710 16708 16606 16552>,
			<17171 16823 16664 16703 16628 16572>,
			<17146 16824 16637 16690 16634 16578>,
			<17158 16809 16623 16626 16596 16557>,
			<17173 16791 16616 16565 16546 16526>,
			<17165 16789 16617 16543 16519 16504>,
			<17131 16788 16620 16529 16498 16485>,
			<17115 16784 16622 16527 16492 16480>,
			<17115 16753 16625 16533 16497 16483>,
			<17115 16722 16626 16541 16505 16488>,
			<17115 16734 16622 16548 16514 16494>,
			<17114 16769 16612 16555 16528 16503>,
			<17114 16780 16606 16566 16541 16514>,
			<17116 16765 16602 16579 16555 16529>,
			<17120 16752 16599 16590 16563 16541>,
			<17124 16757 16602 16599 16563 16544>,
			<17132 16770 16610 16606 16562 16546>,
			<17141 16773 16618 16602 16558 16544>,
			<17150 16769 16629 16586 16535 16518>,
			<17161 16766 16637 16574 16512 16495>,
			<17182 16768 16640 16567 16506 16490>,
			<17216 16776 16642 16562 16503 16487>,
			<17251 16795 16643 16560 16502 16487>,
			<17285 16862 16644 16559 16505 16487>,
			<17316 16902 16638 16555 16505 16485>,
			<17347 16918 16620 16540 16496 16473>,
			<17323 16932 16638 16517 16481 16466>,
			<17141 16907 16642 16547 16500 16477>,
			<17152 16930 16651 16573 16518 16494>,
			<17169 16969 16682 16595 16531 16521>,
			<17181 17012 16712 16614 16553 16542>,
			<17180 17053 16737 16604 16518 16488>,
			<17176 17047 16713 16561 16494 16476>,
			<17171 17046 16705 16556 16494 16479>,
			<17170 17091 16743 16569 16505 16496>,
			<17360 17181 16813 16638 16574 16585>,
			<17360 17181 16813 16638 16574 16585>,
			<17360 17181 16813 16638 16574 16585>;
	};

	qcom,pc-temp-y5-lut {
		qcom,lut-col-legend = <(-10) 0 10 25 40 50>;
		qcom,lut-row-legend = <10000 9800 9600 9400 9200 9000>,
			<8800 8600 8400 8200 8000 7800>,
			<7600 7400 7200 7000 6800 6600>,
			<6400 6200 6000 5800 5600 5400>,
			<5200 5000 4800 4600 4400 4200>,
			<4000 3800 3600 3400 3200 3000>,
			<2800 2600 2400 2200 2000 1800>,
			<1600 1400 1200 1000 900 800>,
			<700 600 500 400 300 200>,
			<100 0>;
		qcom,lut-data = <11941 11335 12991 13459 15360 24007>,
			<11683 11716 13026 13663 15475 20700>,
			<11566 12171 13018 13750 15526 18010>,
			<11567 12624 12976 13748 15526 16009>,
			<11659 12999 12908 13683 15485 14771>,
			<11821 13218 12821 13581 15416 14375>,
			<12580 13295 12670 13284 15204 15228>,
			<13543 13357 12527 12970 14861 16416>,
			<13629 13629 12591 13013 14481 16526>,
			<13306 14355 12973 13288 14004 16182>,
			<13119 14729 13383 13397 13796 15741>,
			<13298 14631 13713 12914 14103 15176>,
			<13723 14506 14068 12385 14494 14536>,
			<14728 14742 14487 12423 14320 13952>,
			<17084 15771 14980 12706 13519 13366>,
			<18270 16691 15666 13070 13127 13148>,
			<15896 17396 17153 13566 13122 13333>,
			<12791 17876 18447 14289 13119 13598>,
			<12585 17379 18417 15903 13258 13726>,
			<13368 15642 17938 18238 13830 13803>,
			<13764 14868 17366 19001 14604 13979>,
			<13230 14896 16624 19104 16117 14995>,
			<12432 14926 15828 19144 17403 16012>,
			<11997 14752 15081 18424 17206 16111>,
			<11686 14245 14373 16905 16304 16126>,
			<11502 14093 14129 16007 15590 16096>,
			<11391 15034 14087 15409 15058 15508>,
			<11327 15981 14069 15143 14736 14928>,
			<11323 15155 14663 15569 14724 14920>,
			<11326 12894 16067 16307 14735 14977>,
			<11328 12120 16764 16624 14813 14990>,
			<11319 12627 17057 16747 15626 14900>,
			<11304 13137 17193 16950 16623 14819>,
			<11282 13217 16893 18021 17287 15358>,
			<11249 13249 16303 19246 17837 16568>,
			<11239 13404 16246 19346 17928 16898>,
			<11285 14348 16932 19105 17459 16477>,
			<11334 15135 17443 18735 16832 16002>,
			<11324 15109 17443 17828 16280 15761>,
			<11283 14948 17432 16798 15722 15573>,
			<11275 14498 17316 16218 15310 15374>,
			<11424 12808 16692 15853 15010 15147>,
			<11586 12124 16071 15843 14748 15303>,
			<11699 12025 15333 15843 14548 16195>,
			<11962 12207 13306 15278 15481 14901>,
			<12188 12060 13209 13728 14253 15768>,
			<12227 12195 13979 13397 13541 15079>,
			<12352 12204 14193 13503 14648 15562>,
			<12614 12396 14969 14379 15898 16338>,
			<12681 12639 15154 13721 15672 15797>,
			<12382 12699 13942 14526 14809 15941>,
			<12137 12284 13991 15563 15890 16777>,
			<11978 12215 13995 17281 18990 22199>,
			<11217 11832 15503 19847 21454 22219>,
			<11217 11832 15503 19847 21454 22219>,
			<11217 11832 15503 19847 21454 22219>;
	};

	qcom,pc-temp-y6-lut {
		qcom,lut-col-legend = <(-10) 0 10 25 40 50>;
		qcom,lut-row-legend = <10000 9800 9600 9400 9200 9000>,
			<8800 8600 8400 8200 8000 7800>,
			<7600 7400 7200 7000 6800 6600>,
			<6400 6200 6000 5800 5600 5400>,
			<5200 5000 4800 4600 4400 4200>,
			<4000 3800 3600 3400 3200 3000>,
			<2800 2600 2400 2200 2000 1800>,
			<1600 1400 1200 1000 900 800>,
			<700 600 500 400 300 200>,
			<100 0>;
		qcom,lut-data = <6661 5631 5243 5058 5000 4990>,
			<6635 5631 5240 5056 5000 4989>,
			<6610 5629 5237 5055 5000 4989>,
			<6585 5626 5234 5055 5001 4989>,
			<6560 5622 5231 5056 5002 4989>,
			<6535 5617 5229 5057 5004 4990>,
			<6510 5609 5228 5059 5005 4991>,
			<6486 5601 5228 5062 5007 4994>,
			<6456 5597 5228 5065 5009 4996>,
			<6419 5594 5231 5069 5012 4998>,
			<6401 5593 5234 5073 5015 5000>,
			<6409 5593 5236 5077 5018 5002>,
			<6421 5593 5239 5081 5022 5004>,
			<6403 5596 5246 5087 5025 5007>,
			<6318 5603 5259 5094 5029 5009>,
			<6249 5605 5264 5100 5032 5012>,
			<6215 5574 5259 5107 5036 5015>,
			<6193 5532 5249 5111 5039 5018>,
			<6188 5516 5236 5111 5045 5023>,
			<6186 5508 5217 5111 5052 5028>,
			<6184 5500 5203 5109 5054 5029>,
			<6174 5492 5193 5087 5040 5020>,
			<6162 5486 5187 5065 5021 5007>,
			<6158 5482 5183 5055 5011 4999>,
			<6156 5479 5180 5049 5003 4992>,
			<6156 5478 5180 5047 5001 4990>,
			<6165 5480 5180 5048 5002 4991>,
			<6183 5482 5181 5050 5004 4993>,
			<6201 5483 5184 5053 5007 4995>,
			<6224 5483 5188 5058 5011 4999>,
			<6248 5485 5190 5062 5016 5002>,
			<6271 5498 5191 5066 5022 5006>,
			<6296 5517 5192 5071 5026 5009>,
			<6325 5533 5194 5076 5027 5012>,
			<6359 5551 5197 5079 5027 5013>,
			<6396 5573 5202 5079 5026 5013>,
			<6438 5598 5210 5074 5017 5003>,
			<6485 5626 5218 5071 5009 4995>,
			<6537 5655 5224 5068 5007 4994>,
			<6596 5686 5230 5066 5007 4994>,
			<6658 5720 5235 5066 5007 4994>,
			<6724 5757 5240 5067 5007 4995>,
			<6790 5804 5242 5066 5007 4994>,
			<6857 5864 5244 5063 5004 4990>,
			<6902 5931 5246 5054 5003 4990>,
			<6780 5913 5247 5064 5011 4999>,
			<6850 5967 5266 5074 5017 5005>,
			<6927 6032 5288 5085 5026 5015>,
			<7012 6113 5317 5099 5038 5025>,
			<7092 6205 5338 5092 5024 5004>,
			<7189 6301 5340 5081 5013 5000>,
			<7339 6450 5381 5086 5017 5003>,
			<7540 6714 5457 5101 5027 5015>,
			<8174 7020 5597 5136 5053 5045>,
			<8174 7020 5597 5136 5053 5045>,
			<8174 7020 5597 5136 5053 5045>;
	};

};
